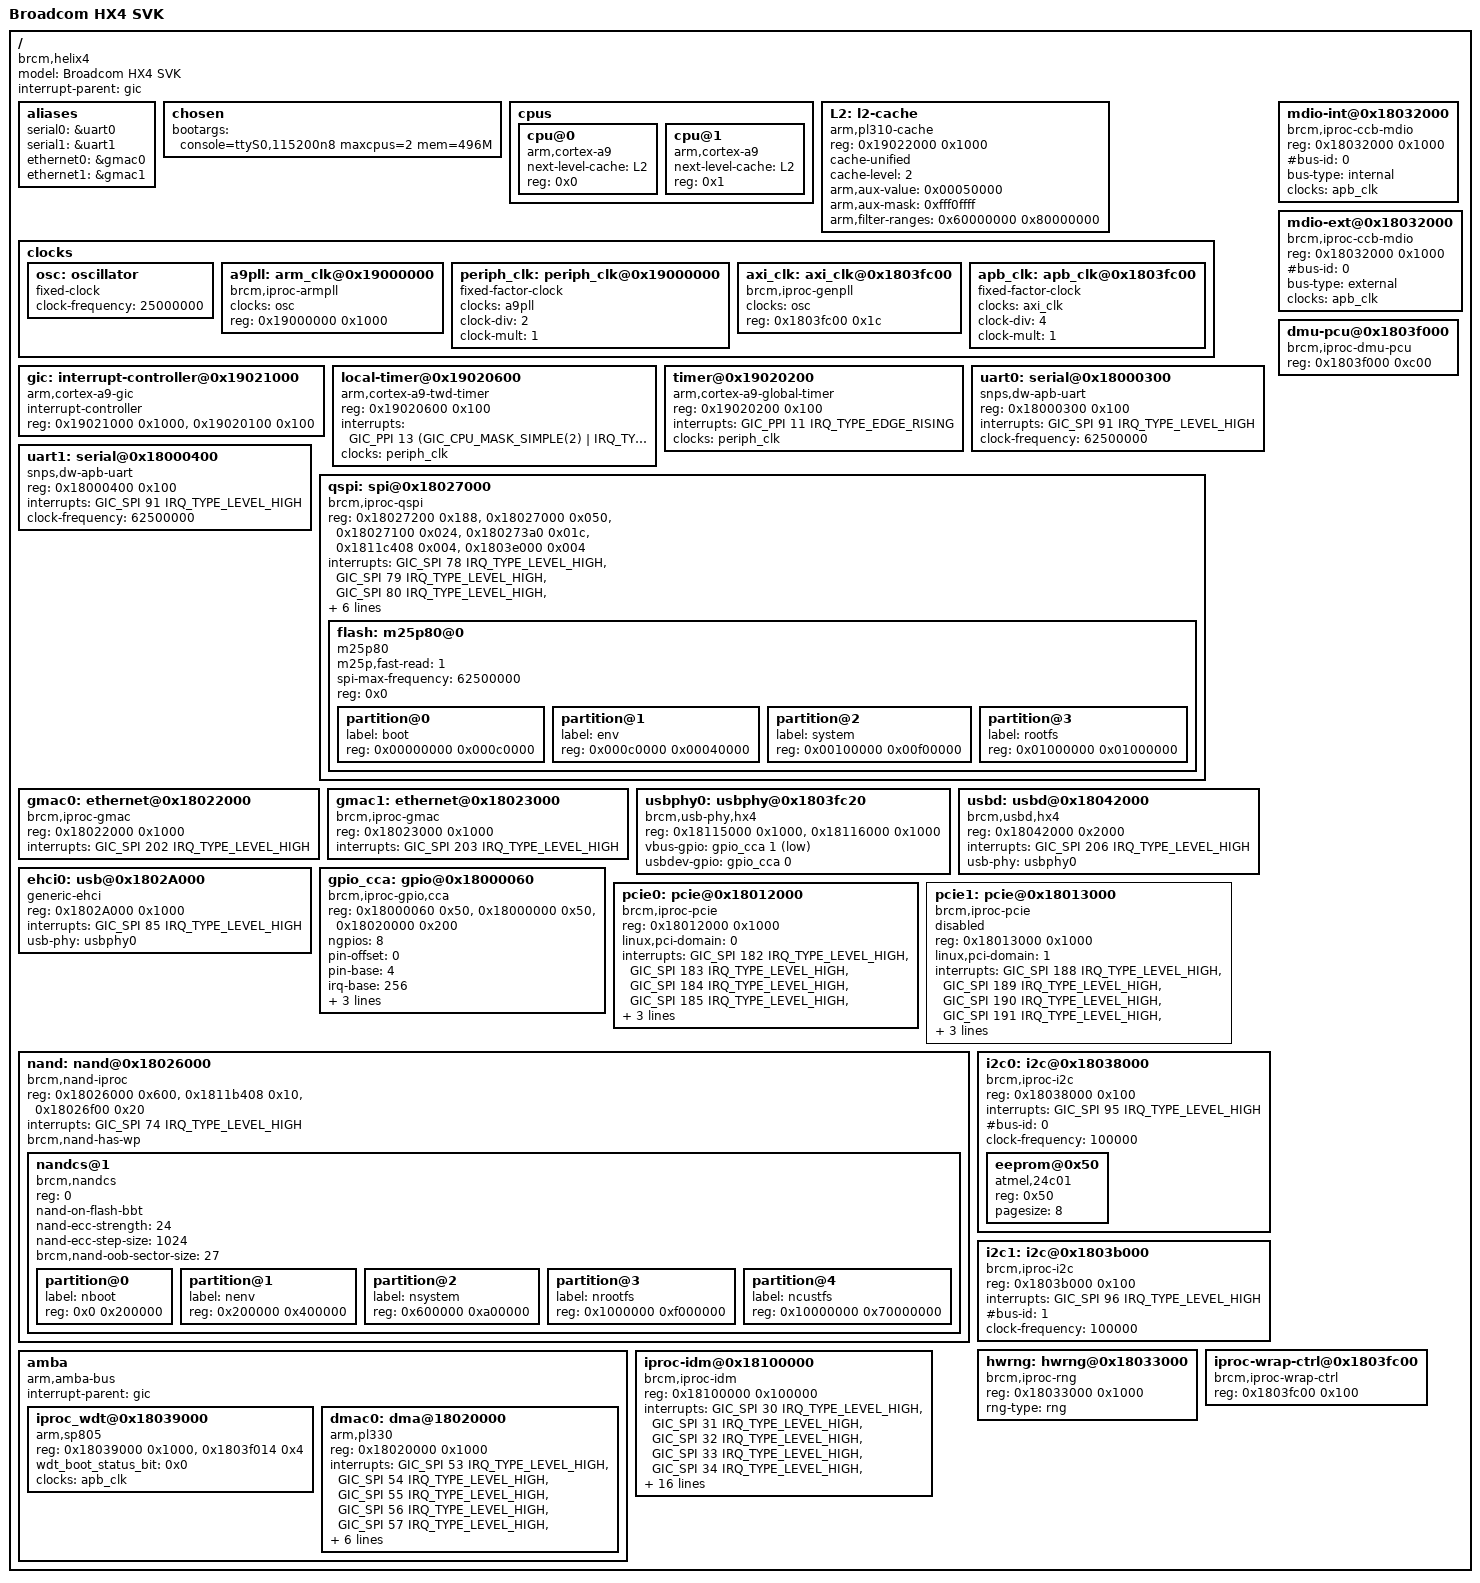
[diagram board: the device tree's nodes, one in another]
/*
 HX4 DTS
*/

/dts-v1/;

#include <dt-bindings/interrupt-controller/arm-gic.h>
#include <dt-bindings/gpio/gpio.h>
#include "skeleton.dtsi"


/ {
	model = "Broadcom HX4 SVK";
	compatible = "brcm,helix4";
	interrupt-parent = <&gic>;

	aliases {
		serial0 = &uart0;
		serial1 = &uart1;
		ethernet0 = &gmac0;
		ethernet1 = &gmac1;
	};
	
	chosen {
		bootargs = "console=ttyS0,115200n8 maxcpus=2 mem=496M";
	};

	cpus {
		#address-cells = <1>;
		#size-cells = <0>;

		cpu@0 {
			device_type = "cpu";
			compatible = "arm,cortex-a9";
			next-level-cache = <&L2>;
			reg = <0x0>;
		};

		cpu@1 {
			device_type = "cpu";
			compatible = "arm,cortex-a9";
			next-level-cache = <&L2>;
			reg = <0x1>;
		};		
	};
 	
  	L2: l2-cache {
		compatible = "arm,pl310-cache";
		reg = <0x19022000 0x1000>;
		cache-unified;
		cache-level = <2>;
		/* aux register value */
		arm,aux-value = <0x00050000>;
		arm,aux-mask = <0xfff0ffff>;
		arm,filter-ranges = <0x60000000 0x80000000>;
		/*arm,data-latency = <2 2 2>;*/
		/*arm,tag-latency = <1 1 1>;*/
	};
  	
  	clocks {
		#address-cells = <1>;
		#size-cells = <1>;
		ranges;

		osc: oscillator {
			#clock-cells = <0>;
			compatible = "fixed-clock";
			clock-frequency = <25000000>;
		};

		a9pll: arm_clk@0x19000000 {
			#clock-cells = <0>;
			compatible = "brcm,iproc-armpll";
			clocks = <&osc>;
			reg = <0x19000000 0x1000>;
		};

		periph_clk: periph_clk@0x19000000 {
			#clock-cells = <0>;
			compatible = "fixed-factor-clock";
			clocks = <&a9pll>;
			clock-div = <2>;
			clock-mult = <1>;
		};

		axi_clk: axi_clk@0x1803fc00 {
			#clock-cells = <0>;
			compatible = "brcm,iproc-genpll";
			clocks = <&osc>;
			reg = <0x1803fc00 0x1c>;
		};

		apb_clk: apb_clk@0x1803fc00 {
			#clock-cells = <0>;
			compatible = "fixed-factor-clock";
			clocks = <&axi_clk>;
			clock-div = <4>;
			clock-mult = <1>;
		};	
	};
  	
  	gic: interrupt-controller@0x19021000 {
		compatible = "arm,cortex-a9-gic";
		#interrupt-cells = <3>;
		interrupt-controller;
		reg = <0x19021000 0x1000>, <0x19020100 0x100>;
	};
  	  
  	local-timer@0x19020600 {
		compatible = "arm,cortex-a9-twd-timer";
		reg = <0x19020600 0x100>;
		/* bits[15:8] of PPI interrupt is cpu mask corresponding to each
		*  of the 8 possible cpus attached to the GIC
		*/
		interrupts = <GIC_PPI 13 (GIC_CPU_MASK_SIMPLE(2) | 
			IRQ_TYPE_EDGE_RISING)>;
		clocks = <&periph_clk>;
	};
  	
  	timer@0x19020200 {
		compatible = "arm,cortex-a9-global-timer";
		reg = <0x19020200 0x100>;
		interrupts = <GIC_PPI 11 IRQ_TYPE_EDGE_RISING>; 
		clocks = <&periph_clk>;
	};
	
	uart0: serial@0x18000300 {
		compatible = "snps,dw-apb-uart";
		reg = <0x18000300 0x100>;
		interrupts = <GIC_SPI 91 IRQ_TYPE_LEVEL_HIGH>;
		clock-frequency = <62500000>;
	};

	uart1: serial@0x18000400 {
		compatible = "snps,dw-apb-uart";
		reg = <0x18000400 0x100>;
		interrupts = <GIC_SPI 91 IRQ_TYPE_LEVEL_HIGH>;
		clock-frequency = <62500000>;
		/*status = "disabled";*/
	};

	qspi: spi@0x18027000 {
		#address-cells = <1>;
		#size-cells = <0>;
		compatible = "brcm,iproc-qspi";
		reg = mspi_hw:<0x18027200 0x188>,
		      bspi_hw:<0x18027000 0x050>,
		  bspi_hw_raf:<0x18027100 0x024>,
		    qspi_intr:<0x180273a0 0x01c>,
		     idm_qspi:<0x1811c408 0x004>,
		       cru_hw:<0x1803e000 0x004>;
		interrupts = <GIC_SPI 78 IRQ_TYPE_LEVEL_HIGH>,
				<GIC_SPI 79 IRQ_TYPE_LEVEL_HIGH>,
				<GIC_SPI 80 IRQ_TYPE_LEVEL_HIGH>,
				<GIC_SPI 81 IRQ_TYPE_LEVEL_HIGH>,
				<GIC_SPI 82 IRQ_TYPE_LEVEL_HIGH>,
				<GIC_SPI 83 IRQ_TYPE_LEVEL_HIGH>,
				<GIC_SPI 84 IRQ_TYPE_LEVEL_HIGH>;
		#chip-select = <0>; 
		clocks = <&apb_clk>;
		clock-names = "apb_clk";
		flash: m25p80@0 {
			#address-cells = <1>;
			#size-cells = <1>;
			compatible = "m25p80";
			m25p,fast-read = <1>;
			spi-max-frequency = <62500000>;
			reg = <0x0>;
			partition@0 {
				label = "boot";
				reg = <0x00000000 0x000c0000>;
				/*read-only;*/
			};
			partition@1 {
				label = "env";
				reg = <0x000c0000 0x00040000>;
			};
			partition@2 {
				label = "system";
				reg = <0x00100000 0x00f00000>;
			};
			partition@3 {
				label = "rootfs";
				reg = <0x01000000 0x01000000>;
			};
		};
	};

	gmac0: ethernet@0x18022000 {
		compatible = "brcm,iproc-gmac";
		reg = <0x18022000 0x1000>;
		interrupts = <GIC_SPI 202 IRQ_TYPE_LEVEL_HIGH>;
	};

	gmac1: ethernet@0x18023000 {
		compatible = "brcm,iproc-gmac";
		reg = <0x18023000 0x1000>;
		interrupts = <GIC_SPI 203 IRQ_TYPE_LEVEL_HIGH>;
		/*status = "disabled";*/
	};

	usbphy0: usbphy@0x1803fc20 {
		#phy-cells = <0>;
		compatible = "brcm,usb-phy,hx4";
		reg = idm_usb2h: <0x18115000 0x1000>, 
			  idm_usb2d: <0x18116000 0x1000>; 
		vbus-gpio = <&gpio_cca 1 GPIO_ACTIVE_LOW>;
		usbdev-gpio = <&gpio_cca 0 GPIO_ACTIVE_HIGH>;	
	};
	
	usbd: usbd@0x18042000 {
		compatible = "brcm,usbd,hx4";
		reg = <0x18042000 0x2000>;
		interrupts = <GIC_SPI 206 IRQ_TYPE_LEVEL_HIGH>;
		usb-phy = <&usbphy0>;
	};

	ehci0: usb@0x1802A000 {
		compatible = "generic-ehci";
		reg = <0x1802A000 0x1000>;
		interrupts = <GIC_SPI 85 IRQ_TYPE_LEVEL_HIGH>;	
		usb-phy = <&usbphy0>;
	};

	gpio_cca: gpio@0x18000060 {
		compatible = "brcm,iproc-gpio,cca";
		#address-cells = <1>;
		#size-cells = <1>;
		#gpio-cells = <2>;
		reg = gpio: <0x18000060 0x50>,
		      intr: <0x18000000 0x50>, 
		       dmu: <0x18020000 0x200>;
		ngpios = <8>;
		pin-offset = <0>;
		pin-base = <4>;
		irq-base = <256>; /* sw irq base for irq handlers */
		gpio-controller;
		interrupt-controller;
		interrupts = <GIC_SPI 91 IRQ_TYPE_LEVEL_HIGH>;
	};
	
	pcie0: pcie@0x18012000 {
		compatible = "brcm,iproc-pcie", "iproc-p2";
		reg = <0x18012000 0x1000>;
		linux,pci-domain = <0>;
		interrupts = <GIC_SPI 182 IRQ_TYPE_LEVEL_HIGH>,
			     <GIC_SPI 183 IRQ_TYPE_LEVEL_HIGH>,
			     <GIC_SPI 184 IRQ_TYPE_LEVEL_HIGH>,
			     <GIC_SPI 185 IRQ_TYPE_LEVEL_HIGH>,
			     <GIC_SPI 186 IRQ_TYPE_LEVEL_HIGH>,
			     <GIC_SPI 187 IRQ_TYPE_LEVEL_HIGH>;
		status = "okay"; 
		#address-cells = <3>;
		#size-cells = <2>;
		device_type = "pci";
		/*non-prefetchable mem space, pcie addr 0x0 0x08000000,
		* cpu addr 0x08000000, size 0x0 0x08000000
		*/  		
		ranges = <0x82000000 0 0x08000000 0x08000000 0 0x08000000>;	
		phy-addr = <0>;
	};

	pcie1: pcie@0x18013000 {
		compatible = "brcm,iproc-pcie", "iproc-p2";
		reg = <0x18013000 0x1000>;
		linux,pci-domain = <1>;
		interrupts = <GIC_SPI 188 IRQ_TYPE_LEVEL_HIGH>,
			     <GIC_SPI 189 IRQ_TYPE_LEVEL_HIGH>,
			     <GIC_SPI 190 IRQ_TYPE_LEVEL_HIGH>,
			     <GIC_SPI 191 IRQ_TYPE_LEVEL_HIGH>,
			     <GIC_SPI 192 IRQ_TYPE_LEVEL_HIGH>,
			     <GIC_SPI 193 IRQ_TYPE_LEVEL_HIGH>;
		status = "disabled";
		#address-cells = <3>;
		#size-cells = <2>;
		device_type = "pci";
		/*non-prefetchable mem space, pcie addr 0x0 0x40000000,
		* cpu addr 0x40000000, size 0x0 0x08000000
		*/  		
		ranges = <0x82000000 0 0x40000000 0x40000000 0 0x08000000>;	
		phy-addr = <1>;
	};

	nand: nand@0x18026000 {
		compatible = "brcm,nand-iproc", "brcm,brcmnand-v6.1";
		reg = <0x18026000 0x600>, <0x1811b408 0x10>, <0x18026f00 0x20>;
		reg-names = "nand", "iproc-idm", "iproc-ext";
		interrupts = <GIC_SPI 74 IRQ_TYPE_LEVEL_HIGH>;
		#address-cells = <1>;
		#size-cells = <0>;
		brcm,nand-has-wp;
		
		nandcs@1 {
			compatible = "brcm,nandcs";
			reg = <0>;
			nand-on-flash-bbt;
			/*nand-bus-width = <8>;*/
			nand-ecc-strength = <24>;
			nand-ecc-step-size = <1024>;
			brcm,nand-oob-sector-size = <27>;

			#address-cells = <1>;
			#size-cells = <1>;
			
			partition@0 {
				label = "nboot";
				reg = <0x0 0x200000>;
				/*read-only;*/
			};
			partition@1 {
				label = "nenv";
				reg = <0x200000 0x400000>;
			};
			partition@2 {
				label = "nsystem";
				reg = <0x600000 0xa00000>;
			};
			partition@3 {
				label = "nrootfs";
				reg = <0x1000000 0xf000000>;
			};
			partition@4 {
				label = "ncustfs";
				reg = <0x10000000 0x70000000>;
			};		
		};
	};

	i2c0: i2c@0x18038000 {
		compatible = "brcm,iproc-i2c";
		reg = <0x18038000 0x100>;
		interrupts = <GIC_SPI 95 IRQ_TYPE_LEVEL_HIGH>;
		#bus-id = <0>;
		clock-frequency = <100000>;
	
		#address-cells = <1>;
		#size-cells = <0>;	
		eeprom@0x50 {
			compatible = "atmel,24c01";
			reg = <0x50>;
			pagesize = <8>;
		};
	};
	
	i2c1: i2c@0x1803b000 {
		compatible = "brcm,iproc-i2c";
		reg = <0x1803b000 0x100>;
		interrupts = <GIC_SPI 96 IRQ_TYPE_LEVEL_HIGH>;
		#bus-id = <1>;
		clock-frequency = <100000>;
	};
	
	mdio-int@0x18032000 {
		compatible = "brcm,iproc-ccb-mdio";
		#address-cells = <1>;
		#size-cells = <1>;
		reg = <0x18032000 0x1000>;
		#bus-id = <0>;
		bus-type = "internal";
		clocks = <&apb_clk>;
		clock-names = "apb_clk";
	};
	
	mdio-ext@0x18032000 {
		compatible = "brcm,iproc-ccb-mdio";
		#address-cells = <1>;
		#size-cells = <1>;
		reg = <0x18032000 0x1000>;
		#bus-id = <0>;
		bus-type = "external";
		clocks = <&apb_clk>;
		clock-names = "apb_clk";
	};
		
	hwrng: hwrng@0x18033000 {
		compatible = "brcm,iproc-rng";
		#address-cells = <1>;
		#size-cells = <1>;
		reg = <0x18033000 0x1000>;
		rng-type = "rng";
	};
	
	amba {
		#address-cells = <1>;
		#size-cells = <1>;
		compatible = "arm,amba-bus", "simple-bus";
		interrupt-parent = <&gic>;
		ranges;

		iproc_wdt@0x18039000 {
			compatible = "arm,sp805", "arm,primecell";
			reg = iproc_wdt_base: <0x18039000 0x1000>,
	      		iproc_reset_reg: <0x1803f014 0x4>;
	      	wdt_boot_status_bit = <0x0>;	
			clocks = <&apb_clk>;
			/* should be "apb_pclk" according to 
			*Documentation/devicetree/bindings/arm/primecell.txt
			*/
			clock-names = "apb_pclk";
		};
				
		dmac0: dma@18020000 {
			compatible = "arm,pl330", "arm,primecell";
			reg = pl330_base: <0x18020000 0x1000>;
			interrupts = <GIC_SPI 53 IRQ_TYPE_LEVEL_HIGH>, 
            			<GIC_SPI 54 IRQ_TYPE_LEVEL_HIGH>,
            			<GIC_SPI 55 IRQ_TYPE_LEVEL_HIGH>,
            			<GIC_SPI 56 IRQ_TYPE_LEVEL_HIGH>,
            			<GIC_SPI 57 IRQ_TYPE_LEVEL_HIGH>,
            			<GIC_SPI 58 IRQ_TYPE_LEVEL_HIGH>,
            			<GIC_SPI 59 IRQ_TYPE_LEVEL_HIGH>,
            			<GIC_SPI 60 IRQ_TYPE_LEVEL_HIGH>; 
				/*arm,primecell-periphid = <0x00041330>;*/
				clocks = <&apb_clk>;
				clock-names = "apb_pclk";
				#dma-cells = <1>;
				#dma-channels = <8>;
				#dma-requests = <16>;
		};        
	};
	
	dmu-pcu@0x1803f000 {
		compatible = "brcm,iproc-dmu-pcu";
		#address-cells = <1>;
		#size-cells = <1>;
		reg = dmu_pcu: <0x1803f000 0xc00>;
	};
	
	iproc-wrap-ctrl@0x1803fc00 {
		compatible = "brcm,iproc-wrap-ctrl";
		#address-cells = <1>;
		#size-cells = <1>;
		reg = <0x1803fc00 0x100>;
	};
	
	iproc-idm@0x18100000 {
		compatible = "brcm,iproc-idm";
		#address-cells = <1>;
		#size-cells = <1>;
		reg = <0x18100000 0x100000>;
		interrupts = <GIC_SPI 30 IRQ_TYPE_LEVEL_HIGH>,
				<GIC_SPI 31 IRQ_TYPE_LEVEL_HIGH>,
				<GIC_SPI 32 IRQ_TYPE_LEVEL_HIGH>,
				<GIC_SPI 33 IRQ_TYPE_LEVEL_HIGH>,
				<GIC_SPI 34 IRQ_TYPE_LEVEL_HIGH>,
				<GIC_SPI 35 IRQ_TYPE_LEVEL_HIGH>,
				<GIC_SPI 36 IRQ_TYPE_LEVEL_HIGH>,
				<GIC_SPI 37 IRQ_TYPE_LEVEL_HIGH>,
				<GIC_SPI 38 IRQ_TYPE_LEVEL_HIGH>,
				<GIC_SPI 39 IRQ_TYPE_LEVEL_HIGH>,
				<GIC_SPI 41 IRQ_TYPE_LEVEL_HIGH>,
				<GIC_SPI 42 IRQ_TYPE_LEVEL_HIGH>,
				<GIC_SPI 43 IRQ_TYPE_LEVEL_HIGH>,
				<GIC_SPI 44 IRQ_TYPE_LEVEL_HIGH>,
				<GIC_SPI 45 IRQ_TYPE_LEVEL_HIGH>,  
				<GIC_SPI 46 IRQ_TYPE_LEVEL_HIGH>,
				<GIC_SPI 47 IRQ_TYPE_LEVEL_HIGH>,
				<GIC_SPI 48 IRQ_TYPE_LEVEL_HIGH>,
				<GIC_SPI 49 IRQ_TYPE_LEVEL_HIGH>,  
				<GIC_SPI 50 IRQ_TYPE_LEVEL_HIGH>,    
				<GIC_SPI 51 IRQ_TYPE_LEVEL_HIGH>; 
	};		
};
